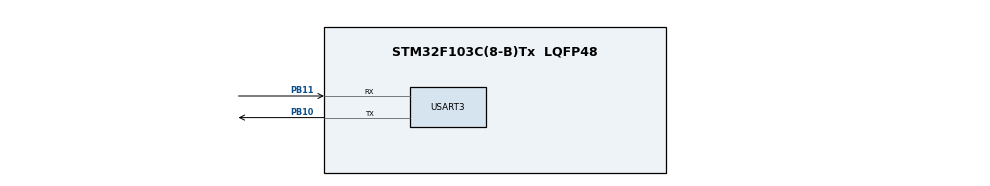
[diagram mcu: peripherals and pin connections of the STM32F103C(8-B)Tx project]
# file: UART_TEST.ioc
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Mcu.Family=STM32F1
Mcu.Name=STM32F103C(8-B)Tx
Mcu.Package=LQFP48
NVIC.PriorityGroup=NVIC_PRIORITYGROUP_4
NVIC.USART3_IRQn=true\:0\:0\:false\:false\:true\:true\:true\:true
PA13.Mode=Serial_Wire
PA13.Signal=SYS_JTMS-SWDIO
PA14.Mode=Serial_Wire
PA14.Signal=SYS_JTCK-SWCLK
PB10.Mode=Asynchronous
PB10.Signal=USART3_TX
PB11.Mode=Asynchronous
PB11.Signal=USART3_RX
PB8.Signal=I2C1_SCL
ProjectManager.HeapSize=0x200
ProjectManager.StackSize=0x400
ProjectManager.TargetToolchain=STM32CubeIDE
RCC.APB1Freq_Value=8000000
RCC.APB2Freq_Value=8000000
USART3.VirtualMode=VM_ASYNC
board=custom

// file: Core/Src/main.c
/* USER CODE BEGIN Header */
/**
  ******************************************************************************
  * @file           : main.c
  * @brief          : Main program body
  ******************************************************************************
  * @attention
  *
  * Copyright (c) 2023 STMicroelectronics.
  * All rights reserved.
  *
  * This software is licensed under terms that can be found in the LICENSE file
  * in the root directory of this software component.
  * If no LICENSE file comes with this software, it is provided AS-IS.
  *
  ******************************************************************************
  */
/* USER CODE END Header */
#include "main.h"

/* USER CODE BEGIN Includes */
#include "string.h"
#include "stdio.h"
/* USER CODE END Includes */

/* USER CODE BEGIN PD */

#define FLAGSET(FLAG,flag)  (flag |= (FLAG))
#define FLAGCLEAR(FLAG,flag)(flag &= ~(FLAG))
#define FLAGCHECK(FLAG,flag)(flag & FLAG ? 1 : 0)

#define FLAG_COMPLETE_UART  (1<<0)

/* USER CODE END PD */

UART_HandleTypeDef huart3;

/* USER CODE BEGIN PV */

uint8_t flag = 0;

uint8_t rxTemp[1] = {0};
uint8_t sRx[50] = {0};
uint8_t sTx[50] = {0};

char* s = "OK\n";

/* USER CODE END PV */

void SystemClock_Config(void);
static void MX_GPIO_Init(void);
static void MX_USART3_UART_Init(void);

/* USER CODE BEGIN 0 */
void HAL_UART_RxCpltCallback(UART_HandleTypeDef *huart){
	if(huart -> Instance == USART3){
		HAL_UART_Receive_IT(huart, rxTemp, 1);
		if(!strcmp((char *)rxTemp,"\n")){
			FLAGSET(FLAG_COMPLETE_UART,flag);
			rxTemp[0] = 0;
		}else
			strcpy((char *)sRx, (char *)rxTemp);
	}
}
/* USER CODE END 0 */

int main(void)
{

  /* MCU Configuration--------------------------------------------------------*/

  /* Reset of all peripherals, Initializes the Flash interface and the Systick. */
  HAL_Init();

  /* Configure the system clock */
  SystemClock_Config();

  /* Initialize all configured peripherals */
  MX_GPIO_Init();
  MX_USART3_UART_Init();
  /* USER CODE BEGIN 2 */

  HAL_UART_Receive_IT(&huart3, rxTemp, 1);

  /* USER CODE END 2 */

  /* Infinite loop */
  /* USER CODE BEGIN WHILE */
  while (1)
  {

	HAL_UART_Transmit(&huart3, (uint8_t*)("OK\n"), strlen("OK\n"), HAL_MAX_DELAY);
	HAL_Delay(1000);
    /* USER CODE END WHILE */

  }
}

void SystemClock_Config(void)
{
  RCC_OscInitTypeDef RCC_OscInitStruct = {0};
  RCC_ClkInitTypeDef RCC_ClkInitStruct = {0};

  /** Initializes the RCC Oscillators according to the specified parameters
  * in the RCC_OscInitTypeDef structure.
  */
  RCC_OscInitStruct.OscillatorType = RCC_OSCILLATORTYPE_HSI;
  RCC_OscInitStruct.HSIState = RCC_HSI_ON;
  RCC_OscInitStruct.HSICalibrationValue = RCC_HSICALIBRATION_DEFAULT;
  RCC_OscInitStruct.PLL.PLLState = RCC_PLL_NONE;
  if (HAL_RCC_OscConfig(&RCC_OscInitStruct) != HAL_OK)
  {
    Error_Handler();
  }

  /** Initializes the CPU, AHB and APB buses clocks
  */
  RCC_ClkInitStruct.ClockType = RCC_CLOCKTYPE_HCLK|RCC_CLOCKTYPE_SYSCLK
                              |RCC_CLOCKTYPE_PCLK1|RCC_CLOCKTYPE_PCLK2;
  RCC_ClkInitStruct.SYSCLKSource = RCC_SYSCLKSOURCE_HSI;
  RCC_ClkInitStruct.AHBCLKDivider = RCC_SYSCLK_DIV1;
  RCC_ClkInitStruct.APB1CLKDivider = RCC_HCLK_DIV1;
  RCC_ClkInitStruct.APB2CLKDivider = RCC_HCLK_DIV1;

  if (HAL_RCC_ClockConfig(&RCC_ClkInitStruct, FLASH_LATENCY_0) != HAL_OK)
  {
    Error_Handler();
  }
}

static void MX_USART3_UART_Init(void)
{

  huart3.Instance = USART3;
  huart3.Init.BaudRate = 115200;
  huart3.Init.WordLength = UART_WORDLENGTH_8B;
  huart3.Init.StopBits = UART_STOPBITS_1;
  huart3.Init.Parity = UART_PARITY_NONE;
  huart3.Init.Mode = UART_MODE_TX_RX;
  huart3.Init.HwFlowCtl = UART_HWCONTROL_NONE;
  huart3.Init.OverSampling = UART_OVERSAMPLING_16;
  if (HAL_UART_Init(&huart3) != HAL_OK)
  {
    Error_Handler();
  }

}

static void MX_GPIO_Init(void)
{
  GPIO_InitTypeDef GPIO_InitStruct = {0};

  /* GPIO Ports Clock Enable */
  __HAL_RCC_GPIOB_CLK_ENABLE();
  __HAL_RCC_GPIOA_CLK_ENABLE();

  /*Configure GPIO pin : PB8 */
  GPIO_InitStruct.Pin = GPIO_PIN_8;
  GPIO_InitStruct.Mode = GPIO_MODE_AF_OD;
  GPIO_InitStruct.Speed = GPIO_SPEED_FREQ_HIGH;
  HAL_GPIO_Init(GPIOB, &GPIO_InitStruct);

  /*Configure peripheral I/O remapping */
  __HAL_AFIO_REMAP_I2C1_ENABLE();

}

void Error_Handler(void)
{
  __disable_irq();
  while (1)
  {
  }
}
